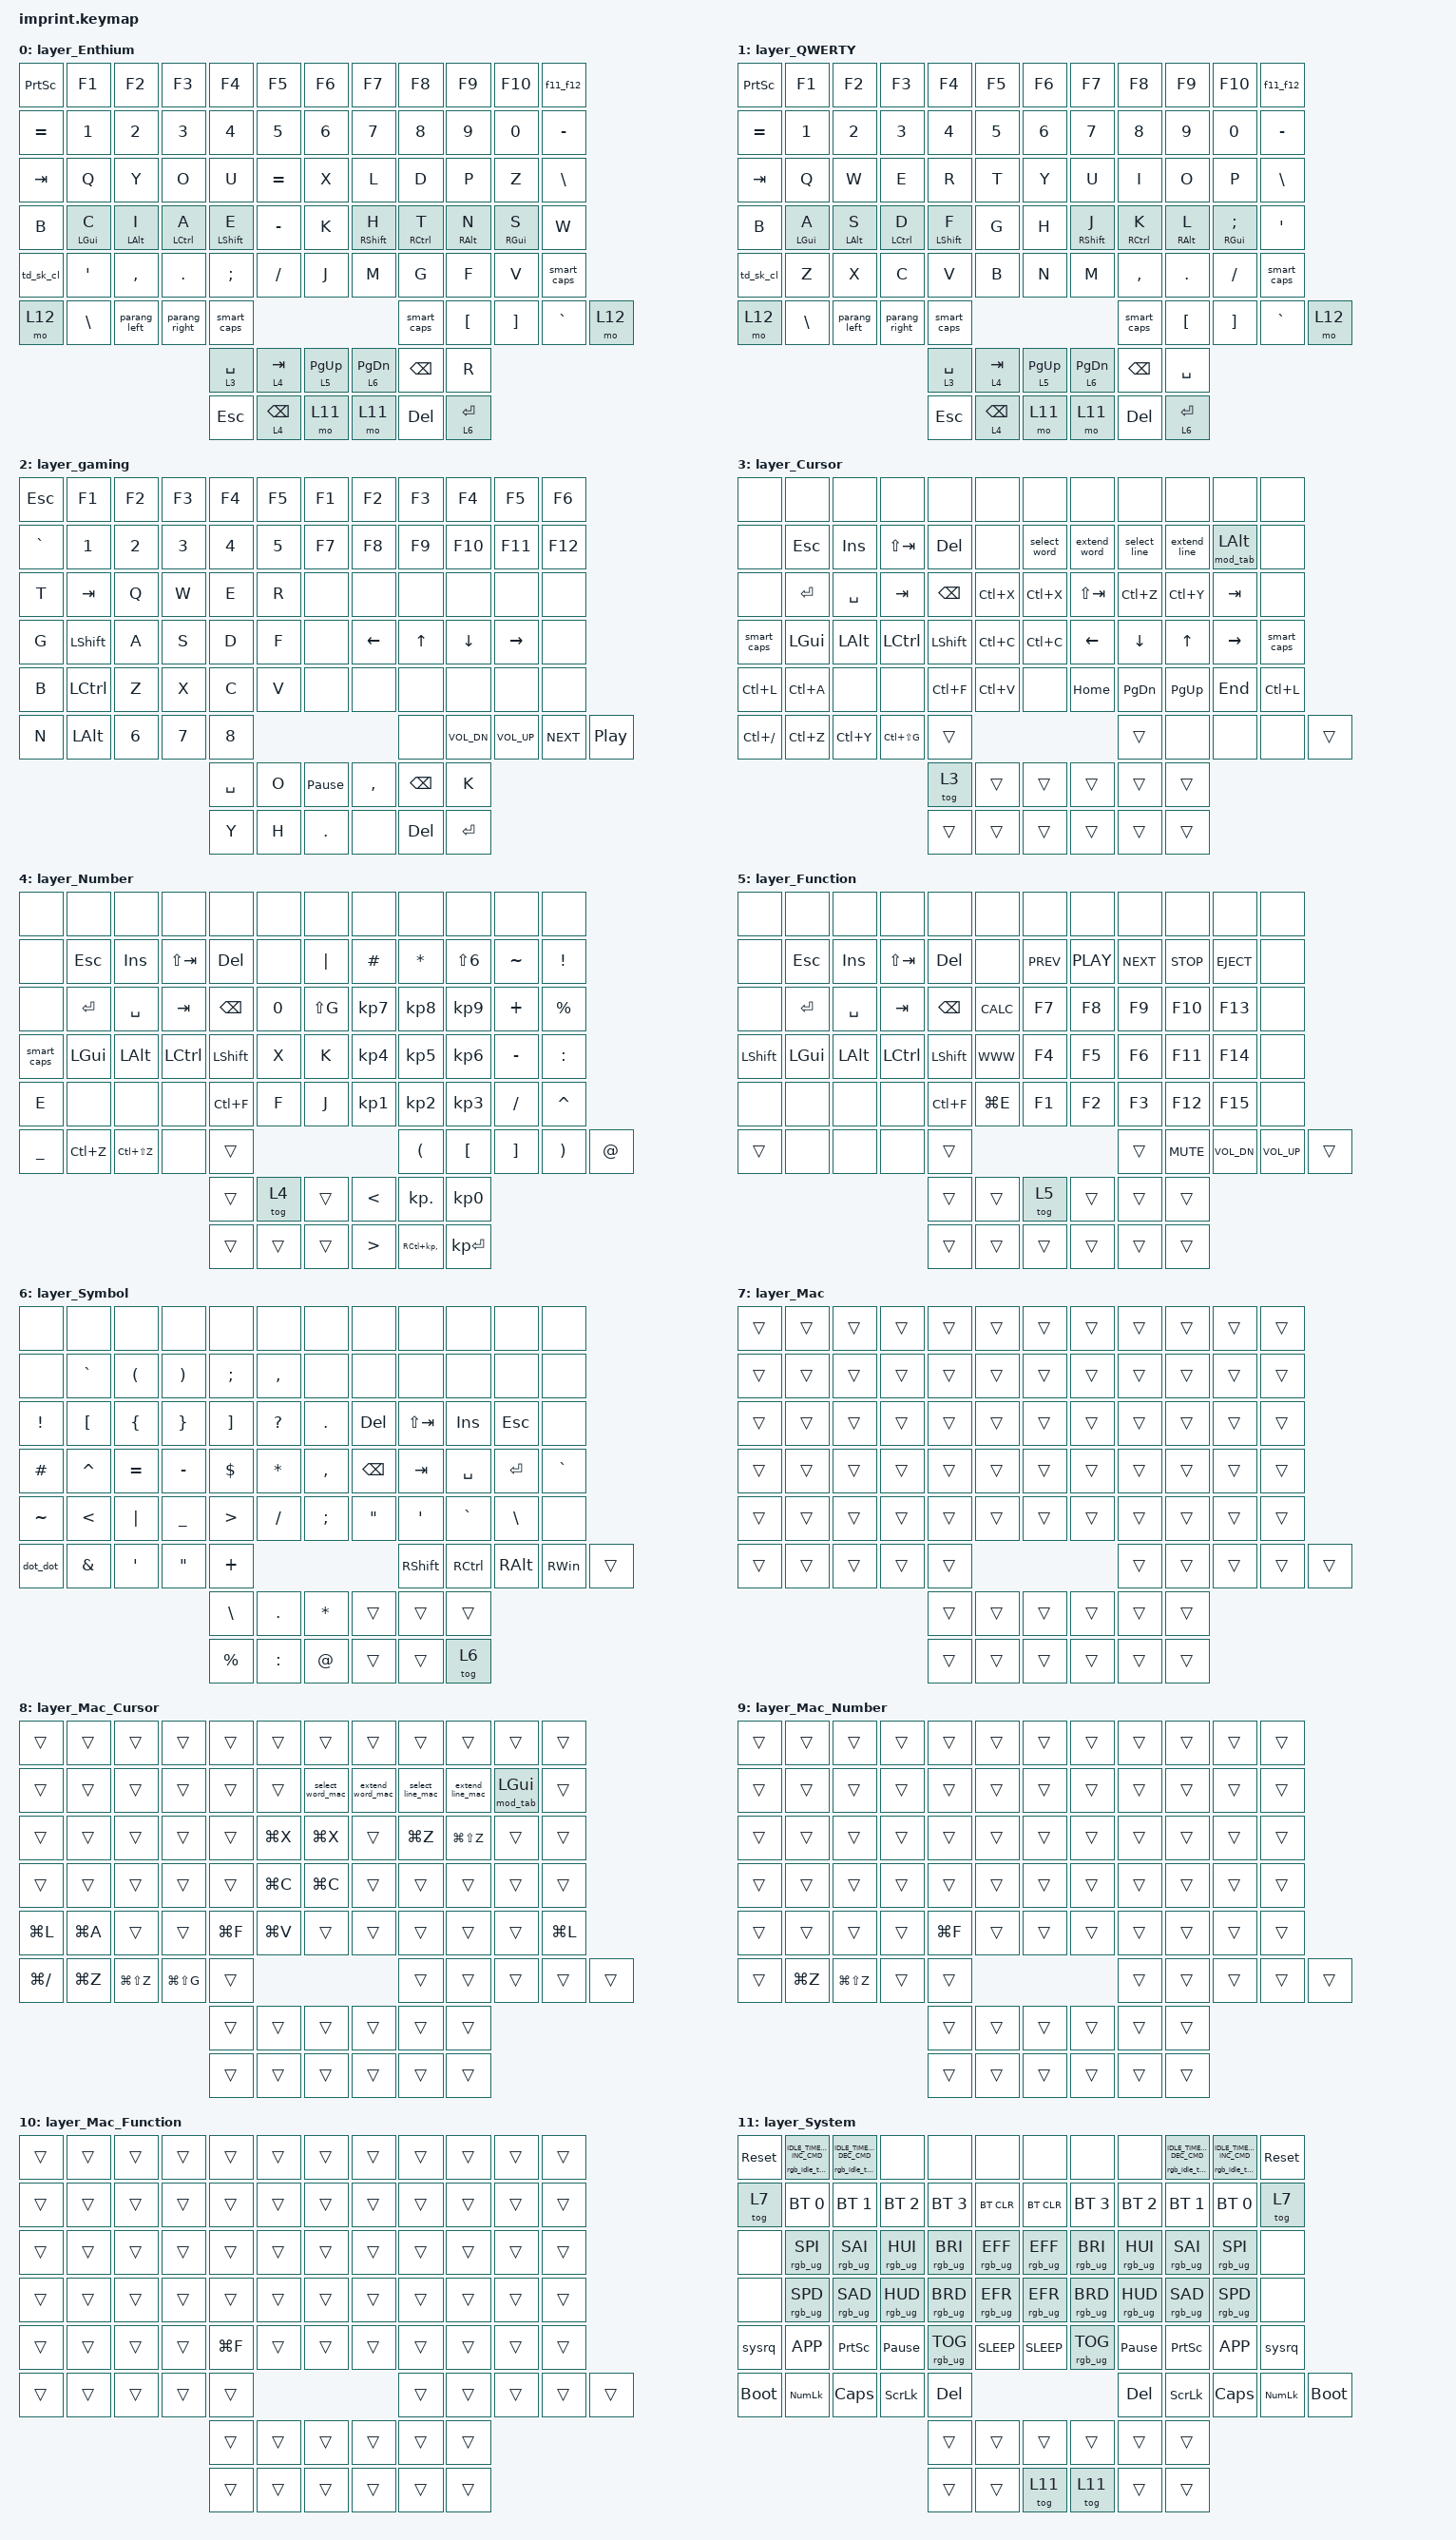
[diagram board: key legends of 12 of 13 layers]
#include <input/processors.dtsi>
#include <dt-bindings/zmk/input_transform.h>
#include <dt-bindings/zmk/hid_usage.h>
#include <behaviors.dtsi>
#include <behaviors/rgb_idle_timeout.dtsi>
#include <dt-bindings/zmk/bt.h>
#include <dt-bindings/zmk/keys.h>
#include <dt-bindings/zmk/rgb.h>
#include <dt-bindings/zmk/rgb_idle_timeout.h>

/ {
    // ========================================================================
    // ADVANCED BEHAVIORS (Adapted from Sunaku's "Glorious Engrammer")
    // ========================================================================

    behaviors {
        // 1. HOME ROW MODS (HRM) - BILATERAL COMBINATIONS
        // Sunaku's "Difficulty Level 2" translates to roughly 200ms tap terms 
        // with a 150ms streak decay. This ensures that at 90wpm, rolling keys 
        // won't accidentally trigger a Shift or Ctrl.

        hm_l: homerow_mods_left {
            compatible = "zmk,behavior-hold-tap";
            label = "HOMEROW_MODS_LEFT";
            #binding-cells = <2>;
            flavor = "balanced";
            tapping-term-ms = <200>;
            quick-tap-ms = <150>;
            require-prior-idle-ms = <50>;

            // NOTE: To make this strictly bilateral (only fires when you press
            // a key on the opposite hand), you must define your right hand key positions.
            // hold-trigger-key-positions = < 6 7 8 ... >;

            bindings = <&kp>, <&kp>;

            hold-trigger-key-positions = <70 76 77 71 78 72 73 74 75 79 80 81 6 7 8 9 10 11 18 19 20 21 22 23 30 31 32 33 34 35 42 43 44 45 46 47 54 55 56 57 58 59 65 66 67 68 69 75 37 38 39 40>;
        };

        hm_r: homerow_mods_right {
            compatible = "zmk,behavior-hold-tap";
            label = "HOMEROW_MODS_RIGHT";
            #binding-cells = <2>;
            flavor = "balanced";
            tapping-term-ms = <200>;
            quick-tap-ms = <150>;
            require-prior-idle-ms = <50>;

            // hold-trigger-key-positions = < 0 1 2 ... >; // Map to left hand keys

            bindings = <&kp>, <&kp>;

            hold-trigger-key-positions = <73 74 75 79 80 81 70 71 72 76 77 78 0 1 2 3 4 5 12 13 14 15 16 17 24 25 26 27 28 29 36 37 38 39 40 41 48 49 50 51 52 53 60 61 62 63 64 46 45 44 43>;
        };

        hm_l_sft: homerow_mods_left_shift {
            compatible = "zmk,behavior-hold-tap";
            label = "HOMEROW_MODS_LEFT_SHIFT";
            #binding-cells = <2>;
            flavor = "balanced";
            tapping-term-ms = <300>;
            quick-tap-ms = <150>;
            require-prior-idle-ms = <50>;
            hold-while-undecided;

            bindings = <&kp>, <&kp>;

            hold-trigger-key-positions = <70 76 77 71 78 72 73 74 75 79 80 81 6 7 8 9 10 11 18 19 20 21 22 23 30 31 32 33 34 35 42 43 44 45 46 47 54 55 56 57 58 59 65 66 67 68 69 75 37 38 39 40>;
        };

        hm_r_sft: homerow_mods_right_shift {
            compatible = "zmk,behavior-hold-tap";
            label = "HOMEROW_MODS_RIGHT_SHIFT";
            #binding-cells = <2>;
            flavor = "balanced";
            tapping-term-ms = <300>;
            quick-tap-ms = <150>;
            require-prior-idle-ms = <50>;
            hold-while-undecided;

            bindings = <&kp>, <&kp>;

            hold-trigger-key-positions = <73 74 75 79 80 81 70 71 72 76 77 78 0 1 2 3 4 5 12 13 14 15 16 17 24 25 26 27 28 29 36 37 38 39 40 41 48 49 50 51 52 53 60 61 62 63 64 46 45 44 43>;
        };

        // 2. THUMB LAYER ACCESS
        // Thumbs use a "balanced" flavor so that if you press a thumb and a key
        // almost simultaneously, it still registers as a layer shift.

        thumb: thumb_layer_access {
            compatible = "zmk,behavior-hold-tap";
            label = "THUMB_LAYER";
            #binding-cells = <2>;
            flavor = "balanced";
            tapping-term-ms = <200>;
            quick-tap-ms = <150>;
            bindings = <&mo>, <&kp>;
        };

        // 3. ONE-SHOT STICKY KEYS
        // For fast capitalization without holding shift. Tap once for next key, 
        // tap twice to lock.

        skq: sticky_key_quick_release {
            compatible = "zmk,behavior-sticky-key";
            label = "STICKY_KEY_QUICK";
            #binding-cells = <1>;
            bindings = <&kp>;
            release-after-ms = <500>;
            quick-release;
            ignore-modifiers;
        };

        // 4. SMART CAPS WORD
        // Automatically turns off caps when you hit space or a non-word character.

        smart_caps: caps_word {
            compatible = "zmk,behavior-caps-word";
            label = "SMART_CAPS";
            #binding-cells = <0>;
            continue-list = <UNDERSCORE MINUS BSPC DEL N1 N2 N3 N4 N5 N6 N7 N8 N9 N0>;
        };

        td_sk_cl: td_sticky_caps_tog {
            compatible = "zmk,behavior-tap-dance";
            label = "TD_SK_CL";
            #binding-cells = <0>;
            bindings = <&smart_caps>, <&kp CAPS>;

            tapping-term-ms = <170>;
        };

        f11_f12: f11_f12 {
            compatible = "zmk,behavior-tap-dance";
            label = "F11_F12";
            #binding-cells = <0>;
            bindings = <&kp F11>, <&kp F12>;
        };

        select_word: select_word {
            compatible = "zmk,behavior-mod-morph";
            #binding-cells = <0>;
            bindings = <&select_word_right>, <&select_word_left>;
            mods = <(MOD_LSFT|MOD_RSFT)>;
        };

        extend_word: extend_word {
            compatible = "zmk,behavior-mod-morph";
            #binding-cells = <0>;
            bindings = <&extend_word_right>, <&extend_word_left>;
            mods = <(MOD_LSFT|MOD_RSFT)>;
        };

        select_line: select_line {
            compatible = "zmk,behavior-mod-morph";
            #binding-cells = <0>;
            bindings = <&select_line_right>, <&select_line_left>;
            mods = <(MOD_LSFT|MOD_RSFT)>;
        };

        extend_line: extend_line {
            compatible = "zmk,behavior-mod-morph";
            #binding-cells = <0>;
            bindings = <&extend_line_right>, <&extend_line_left>;
            mods = <(MOD_LSFT|MOD_RSFT)>;
        };

        select_word_mac: select_word_mac {
            compatible = "zmk,behavior-mod-morph";
            #binding-cells = <0>;
            bindings = <&select_word_right_mac>, <&select_word_left_mac>;
            mods = <(MOD_LSFT|MOD_RSFT)>;
        };

        extend_word_mac: extend_word_mac {
            compatible = "zmk,behavior-mod-morph";
            #binding-cells = <0>;
            bindings = <&extend_word_right_mac>, <&extend_word_left_mac>;
            mods = <(MOD_LSFT|MOD_RSFT)>;
        };

        select_line_mac: select_line_mac {
            compatible = "zmk,behavior-mod-morph";
            #binding-cells = <0>;
            bindings = <&select_line_right_mac>, <&select_line_left_mac>;
            mods = <(MOD_LSFT|MOD_RSFT)>;
        };

        extend_line_mac: extend_line_mac {
            compatible = "zmk,behavior-mod-morph";
            #binding-cells = <0>;
            bindings = <&extend_line_right_mac>, <&extend_line_left_mac>;
            mods = <(MOD_LSFT|MOD_RSFT)>;
        };

        parang_left: parang_left {
            compatible = "zmk,behavior-mod-morph";
            #binding-cells = <0>;
            bindings = <&kp LPAR>, <&kp LESS_THAN>;
            mods = <(MOD_LSFT|MOD_RSFT)>;
        };

        parang_right: parang_right {
            compatible = "zmk,behavior-mod-morph";
            #binding-cells = <0>;
            bindings = <&kp RPAR>, <&kp GREATER_THAN>;
            mods = <(MOD_LSFT|MOD_RSFT)>;
        };
    };

    // ========================================================================
    // MACROS (Rolling bigrams and OS functions)
    // ========================================================================

    macros {
        dot_dot: dot_dot {
            compatible = "zmk,behavior-macro";
            label = "DOT_DOT";
            #binding-cells = <0>;
            wait-ms = <0>;
            tap-ms = <0>;
            bindings = <&kp DOT &kp DOT>;
        };

        // Windows/Linux Magic SysReq

        sysrq: linux_magic_sysrq {
            compatible = "zmk,behavior-macro";
            label = "SYSRQ";
            #binding-cells = <0>;
            wait-ms = <0>;
            tap-ms = <0>;
            bindings =
                <&macro_press>,
                <&kp LALT>,
                <&macro_tap>,
                <&kp PSCRN>,
                <&macro_release>,
                <&kp LALT>;
        };

        select_word_right: select_word_right {
            compatible = "zmk,behavior-macro";
            label = "SELECT_WORD_RIGHT";
            #binding-cells = <0>;
            wait-ms = <1>;
            tap-ms = <1>;
            bindings = <&kp LC(RIGHT) &kp LC(LEFT) &kp LC(LS(RIGHT))>;
        };

        select_word_left: select_word_left {
            compatible = "zmk,behavior-macro";
            label = "SELECT_WORD_LEFT";
            #binding-cells = <0>;
            wait-ms = <1>;
            tap-ms = <1>;
            bindings = <&kp LC(LEFT) &kp LC(RIGHT) &kp LC(LS(LEFT))>;
        };

        extend_word_right: extend_word_right {
            compatible = "zmk,behavior-macro";
            label = "EXTEND_WORD_RIGHT";
            #binding-cells = <0>;
            wait-ms = <1>;
            tap-ms = <1>;
            bindings = <&kp LC(LS(RIGHT))>;
        };

        extend_word_left: extend_word_left {
            compatible = "zmk,behavior-macro";
            label = "EXTEND_WORD_LEFT";
            #binding-cells = <0>;
            wait-ms = <1>;
            tap-ms = <1>;
            bindings = <&kp LC(LS(LEFT))>;
        };

        select_line_right: select_line_right {
            compatible = "zmk,behavior-macro";
            label = "SELECT_LINE_RIGHT";
            #binding-cells = <0>;
            wait-ms = <1>;
            tap-ms = <1>;
            bindings = <&kp HOME &kp LS(END)>;
        };

        select_line_left: select_line_left {
            compatible = "zmk,behavior-macro";
            label = "SELECT_LINE_LEFT";
            #binding-cells = <0>;
            wait-ms = <1>;
            tap-ms = <1>;
            bindings = <&kp END &kp LS(HOME)>;
        };

        extend_line_right: extend_line_right {
            compatible = "zmk,behavior-macro";
            label = "EXTEND_LINE_RIGHT";
            #binding-cells = <0>;
            wait-ms = <1>;
            tap-ms = <1>;
            bindings = <&kp LS(DOWN) &kp LS(END)>;
        };

        extend_line_left: extend_line_left {
            compatible = "zmk,behavior-macro";
            label = "EXTEND_LINE_LEFT";
            #binding-cells = <0>;
            wait-ms = <1>;
            tap-ms = <1>;
            bindings = <&kp LS(UP) &kp LS(HOME)>;
        };

        select_word_right_mac: select_word_right_mac {
            compatible = "zmk,behavior-macro";
            label = "SELECT_WORD_RIGHT_MAC";
            #binding-cells = <0>;
            wait-ms = <1>;
            tap-ms = <1>;
            bindings = <&kp LA(RIGHT) &kp LA(LEFT) &kp LA(LS(RIGHT))>;
        };

        select_word_left_mac: select_word_left_mac {
            compatible = "zmk,behavior-macro";
            label = "SELECT_WORD_LEFT_MAC";
            #binding-cells = <0>;
            wait-ms = <1>;
            tap-ms = <1>;
            bindings = <&kp LA(LEFT) &kp LA(RIGHT) &kp LA(LS(LEFT))>;
        };

        extend_word_right_mac: extend_word_right_mac {
            compatible = "zmk,behavior-macro";
            label = "EXTEND_WORD_RIGHT_MAC";
            #binding-cells = <0>;
            wait-ms = <1>;
            tap-ms = <1>;
            bindings = <&kp LA(LS(RIGHT))>;
        };

        extend_word_left_mac: extend_word_left_mac {
            compatible = "zmk,behavior-macro";
            label = "EXTEND_WORD_LEFT_MAC";
            #binding-cells = <0>;
            wait-ms = <1>;
            tap-ms = <1>;
            bindings = <&kp LA(LS(LEFT))>;
        };

        select_line_right_mac: select_line_right_mac {
            compatible = "zmk,behavior-macro";
            label = "SELECT_LINE_RIGHT_MAC";
            #binding-cells = <0>;
            wait-ms = <1>;
            tap-ms = <1>;
            bindings = <&kp LG(LEFT) &kp LG(LS(RIGHT))>;
        };

        select_line_left_mac: select_line_left_mac {
            compatible = "zmk,behavior-macro";
            label = "SELECT_LINE_LEFT_MAC";
            #binding-cells = <0>;
            wait-ms = <1>;
            tap-ms = <1>;
            bindings = <&kp LG(RIGHT) &kp LG(LS(LEFT))>;
        };

        extend_line_right_mac: extend_line_right_mac {
            compatible = "zmk,behavior-macro";
            label = "EXTEND_LINE_RIGHT_MAC";
            #binding-cells = <0>;
            wait-ms = <1>;
            tap-ms = <1>;
            bindings = <&kp LS(DOWN) &kp LG(LS(RIGHT))>;
        };

        extend_line_left_mac: extend_line_left_mac {
            compatible = "zmk,behavior-macro";
            label = "EXTEND_LINE_LEFT_MAC";
            #binding-cells = <0>;
            wait-ms = <1>;
            tap-ms = <1>;
            bindings = <&kp LS(UP) &kp LG(LS(LEFT))>;
        };

        mod_tab: mod_tab_switcher {
            compatible = "zmk,behavior-macro-one-param";
            label = "MOD_TAB";
            wait-ms = <0>;
            tap-ms = <0>;
            #binding-cells = <1>;
            bindings
                = <&macro_param_1to1>
                , <&macro_press &kp MACRO_PLACEHOLDER>
                , <&macro_tap &kp TAB>
                , <&macro_pause_for_release>
                , <&macro_param_1to1>
                , <&macro_release &kp MACRO_PLACEHOLDER>
                ;
        };
    };

    // ========================================================================
    // KEYMAP LAYERS
    // ========================================================================

    chosen { zmk,matrix-transform = &imprint_function_row_full_bottom_row; };

    combos {
        compatible = "zmk,combos";

        combo_gaming_toggle {
            timeout-ms = <50>;
            require-prior-idle-ms = <150>;
            key-positions = <48 61>;
            bindings = <&tog 2>;
            layers = <0 1 2 7>;
        };

        combo_mac_toggle {
            timeout-ms = <50>;
            require-prior-idle-ms = <150>;
            key-positions = <59 68>;
            bindings = <&tog 7>;
            layers = <0 1 7>;
        };

        combo_sticky_shift_left {
            timeout-ms = <50>;
            require-prior-idle-ms = <150>;
            key-positions = <70 77>;
            bindings = <&sk LSHFT>;
            layers = <0 1 7>;
        };

        combo_sticky_shift_right {
            timeout-ms = <50>;
            require-prior-idle-ms = <150>;
            key-positions = <75 80>;
            bindings = <&sk RSHFT>;
            layers = <0 1 7>;
        };

        combo_caps_word_left {
            timeout-ms = <50>;
            require-prior-idle-ms = <150>;
            key-positions = <76 77>;
            bindings = <&smart_caps>;
            layers = <0 1 7>;
        };

        combo_caps_word_right {
            timeout-ms = <50>;
            require-prior-idle-ms = <150>;
            key-positions = <81 80>;
            bindings = <&smart_caps>;
            layers = <0 1 7>;
        };

        combo_caps_lock_left {
            timeout-ms = <50>;
            require-prior-idle-ms = <150>;
            key-positions = <71 78>;
            bindings = <&kp CAPS>;
            layers = <0 1 7>;
        };

        combo_caps_lock_right {
            timeout-ms = <50>;
            require-prior-idle-ms = <150>;
            key-positions = <74 79>;
            bindings = <&kp CAPS>;
            layers = <0 1 7>;
        };

        combo_alt_tab {
            timeout-ms = <50>;
            require-prior-idle-ms = <150>;
            key-positions = <70 76>;
            bindings = <&mod_tab LALT>;
            layers = <0 1 7>;
        };

        combo_ctrl_tab {
            timeout-ms = <50>;
            require-prior-idle-ms = <150>;
            key-positions = <71 77>;
            bindings = <&mod_tab LCTRL>;
            layers = <0 1 7>;
        };

        combo_win_tab {
            timeout-ms = <50>;
            require-prior-idle-ms = <150>;
            key-positions = <72 78>;
            bindings = <&mod_tab LGUI>;
            layers = <0 1 7>;
        };

        combo_sticky_altgr_left {
            timeout-ms = <50>;
            require-prior-idle-ms = <150>;
            key-positions = <70 71>;
            bindings = <&sk RALT>;
            layers = <0 1 7>;
        };

        combo_sticky_altgr_right {
            timeout-ms = <50>;
            require-prior-idle-ms = <150>;
            key-positions = <75 74>;
            bindings = <&sk RALT>;
            layers = <0 1 7>;
        };

        combo_sticky_win_left {
            timeout-ms = <50>;
            require-prior-idle-ms = <150>;
            key-positions = <71 72>;
            bindings = <&sk LGUI>;
            layers = <0 1 7>;
        };

        combo_sticky_win_right {
            timeout-ms = <50>;
            require-prior-idle-ms = <150>;
            key-positions = <74 73>;
            bindings = <&sk RGUI>;
            layers = <0 1 7>;
        };

        combo_hyper {
            timeout-ms = <50>;
            require-prior-idle-ms = <150>;
            key-positions = <75 81>;
            bindings = <&kp LG(LA(LC(LSHFT)))>;
            layers = <0 1 7>;
        };

        combo_meh {
            timeout-ms = <50>;
            require-prior-idle-ms = <150>;
            key-positions = <74 80>;
            bindings = <&kp LA(LC(LSHFT))>;
            layers = <0 1 7>;
        };

        combo_turbo {
            timeout-ms = <50>;
            require-prior-idle-ms = <150>;
            key-positions = <73 79>;
            bindings = <&kp LC(LSHFT)>;
            layers = <0 1 7>;
        };

        combo_base_reset_left {
            timeout-ms = <50>;
            require-prior-idle-ms = <150>;
            key-positions = <70 71 72>;
            bindings = <&to 0>;
            layers = <1 3 4 5 6 7 8 9 10 11>;
        };

        combo_base_reset_right {
            timeout-ms = <50>;
            require-prior-idle-ms = <150>;
            key-positions = <75 74 73>;
            bindings = <&to 0>;
            layers = <1 3 4 5 6 7 8 9 10 11>;
        };
    };

    keymap {
        compatible = "zmk,keymap";

        layer_Enthium {
            bindings = <
&kp PSCRN  &kp F1        &kp F2        &kp F3         &kp F4          &kp F5                 &kp F6  &kp F7         &kp F8         &kp F9        &kp F10       &f11_f12
&kp EQUAL  &kp N1        &kp N2        &kp N3         &kp N4          &kp N5                 &kp N6  &kp N7         &kp N8         &kp N9        &kp N0        &kp MINUS
&kp TAB    &kp Q         &kp Y         &kp O          &kp U           &kp EQUAL              &kp X   &kp L          &kp D          &kp P         &kp Z         &kp BSLH
&kp B      &hm_l LGUI C  &hm_l LALT I  &hm_l LCTRL A  &hm_l_sft LSHFT E   &kp MINUS              &kp K   &hm_r_sft RSHFT H  &hm_r RCTRL T  &hm_r RALT N  &hm_r RGUI S  &kp W
&td_sk_cl  &kp SQT       &kp COMMA     &kp DOT        &kp SEMI        &kp FSLH               &kp J   &kp M          &kp G          &kp F         &kp V         &smart_caps
&mo 12     &kp BSLH      &parang_left      &parang_right       &smart_caps                                    &smart_caps    &kp LBKT       &kp RBKT      &kp GRAVE     &mo 12
                                                      &thumb 3 SPACE  &thumb 4 TAB  &thumb 5 PG_UP  &thumb 6 PG_DN  &kp BSPC  &kp R
                                                      &kp ESC        &thumb 4 BSPC &mo 11   &mo 11  &kp DEL        &thumb 6 RET
            >;
        };

        layer_QWERTY {
            bindings = <
&kp PSCRN  &kp F1        &kp F2        &kp F3         &kp F4          &kp F5                 &kp F6    &kp F7         &kp F8          &kp F9        &kp F10          &f11_f12
&kp EQUAL  &kp N1        &kp N2        &kp N3         &kp N4          &kp N5                 &kp N6    &kp N7         &kp N8          &kp N9        &kp N0           &kp MINUS
&kp TAB    &kp Q         &kp W         &kp E          &kp R           &kp T                  &kp Y     &kp U          &kp I           &kp O         &kp P            &kp BSLH
&kp B      &hm_l LGUI A  &hm_l LALT S  &hm_l LCTRL D  &hm_l_sft LSHFT F   &kp G                  &kp H     &hm_r_sft RSHFT J  &hm_r RCTRL K   &hm_r RALT L  &hm_r RGUI SEMI  &kp SQT
&td_sk_cl  &kp Z         &kp X         &kp C          &kp V           &kp B                  &kp N     &kp M          &kp COMMA       &kp DOT       &kp FSLH         &smart_caps
&mo 12     &kp BSLH      &parang_left      &parang_right       &smart_caps                                      &smart_caps    &kp LBKT        &kp RBKT      &kp GRAVE        &mo 12
                                                      &thumb 3 SPACE  &thumb 4 TAB  &thumb 5 PG_UP  &thumb 6 PG_DN  &kp BSPC  &kp SPACE
                                                      &kp ESC        &thumb 4 BSPC &mo 11   &mo 11    &kp DEL        &thumb 6 RET
            >;
        };

        layer_gaming {
            bindings = <
&kp ESCAPE  &kp F1            &kp F2        &kp F3  &kp F4        &kp F5                     &kp F1     &kp F2         &kp F3        &kp F4        &kp F5      &kp F6
&kp GRAVE   &kp N1            &kp N2        &kp N3  &kp N4        &kp N5                     &kp F7     &kp F8         &kp F9        &kp F10       &kp F11     &kp F12
&kp T       &kp TAB           &kp Q         &kp W   &kp E         &kp R                      &none      &none          &none         &none         &none       &none
&kp G       &kp LEFT_SHIFT    &kp A         &kp S   &kp D         &kp F                      &none      &kp LEFT       &kp UP        &kp DOWN      &kp RIGHT   &none
&kp B       &kp LEFT_CONTROL  &kp Z         &kp X   &kp C         &kp V                      &none      &none          &none         &none         &none       &none
&kp N       &kp LEFT_ALT      &kp NUMBER_6  &kp N7  &kp NUMBER_8                                        &none          &kp C_VOL_DN  &kp C_VOL_UP  &kp C_NEXT  &kp C_PLAY_PAUSE
                                                    &kp SPACE     &kp O   &kp PAUSE_BREAK    &kp COMMA  &kp BACKSPACE  &kp K
                                                    &kp Y         &kp H   &kp PERIOD         &none      &kp DEL        &kp ENTER
            >;
        };

        layer_Cursor {
            bindings = <
&none          &none      &none      &none          &none      &none                &none      &none        &none      &none      &none      &none
&none          &kp ESC    &kp INS    &kp LS(TAB)    &kp DEL    &none                &select_word  &extend_word  &select_line  &extend_line  &mod_tab LALT  &none
&none          &kp RET    &kp SPACE  &kp TAB        &kp BSPC   &kp LC(X)            &kp LC(X)  &kp LS(TAB)  &kp LC(Z)  &kp LC(Y)  &kp TAB    &none
&smart_caps    &kp LGUI   &kp LALT   &kp LCTRL      &kp LSHFT  &kp LC(C)            &kp LC(C)  &kp LEFT     &kp DOWN   &kp UP     &kp RIGHT  &smart_caps
&kp LC(L)      &kp LC(A)  &none      &none          &kp LC(F)  &kp LC(V)            &none      &kp HOME     &kp PG_DN  &kp PG_UP  &kp END    &kp LC(L)
&kp LC(SLASH)  &kp LC(Z)  &kp LC(Y)  &kp LC(LS(G))  &trans                                     &trans       &none      &none      &none      &trans
                                                    &tog 3     &trans     &trans    &trans     &trans       &trans
                                                    &trans     &trans     &trans    &trans     &trans       &trans
            >;
        };

        layer_Number {
            bindings = <
&none           &none      &none          &none        &none      &none             &none             &none                 &none         &none       &none                  &none
&none           &kp ESC    &kp INS        &kp LS(TAB)  &kp DEL    &none             &kp PIPE          &kp HASH              &kp STAR      &kp LS(N6)  &kp TILDE              &kp EXCLAMATION
&none           &kp RET    &kp SPACE      &kp TAB      &kp BSPC   &kp N0            &kp LS(G)         &kp KP_N7             &kp KP_N8     &kp KP_N9   &kp PLUS               &kp PERCENT
&smart_caps     &kp LGUI   &kp LALT       &kp LCTRL    &kp LSHFT  &kp X             &kp K             &kp KP_N4             &kp KP_N5     &kp KP_N6   &kp MINUS              &kp COLON
&kp E           &none      &none          &none        &kp LC(F)  &kp F             &kp J             &kp KP_N1             &kp KP_N2     &kp KP_N3   &kp FSLH               &kp CARET
&kp UNDERSCORE  &kp LC(Z)  &kp LC(LS(Z))  &none        &trans                                         &kp LEFT_PARENTHESIS  &kp LBKT      &kp RBKT    &kp RIGHT_PARENTHESIS  &kp AT_SIGN
                                                       &trans     &tog 4  &trans    &kp LESS_THAN     &kp KP_DOT            &kp KP_N0
                                                       &trans     &trans  &trans    &kp GREATER_THAN  &kp RC(KP_COMMA)      &kp KP_ENTER
            >;
        };

        layer_Function {
            bindings = <
&none      &none     &none      &none        &none      &none                 &none       &none       &none       &none         &none         &none
&none      &kp ESC   &kp INS    &kp LS(TAB)  &kp DEL    &none                 &kp C_PREV  &kp C_PLAY  &kp C_NEXT  &kp C_STOP    &kp C_EJECT   &none
&none      &kp RET   &kp SPACE  &kp TAB      &kp BSPC   &kp K_CALC            &kp F7      &kp F8      &kp F9      &kp F10       &kp F13       &none
&kp LSHFT  &kp LGUI  &kp LALT   &kp LCTRL    &kp LSHFT  &kp K_WWW             &kp F4      &kp F5      &kp F6      &kp F11       &kp F14       &none
&none      &none     &none      &none        &kp LC(F)  &kp LG(E)             &kp F1      &kp F2      &kp F3      &kp F12       &kp F15       &none
&trans     &none     &none      &none        &trans                                       &trans      &kp C_MUTE  &kp C_VOL_DN  &kp C_VOL_UP  &trans
                                             &trans     &trans      &tog 5    &trans      &trans      &trans
                                             &trans     &trans      &trans    &trans      &trans      &trans
            >;
        };

        layer_Symbol {
            bindings = <
&none            &none          &none                 &none                  &none             &none                        &none          &none              &none             &none      &none          &none
&none            &kp GRAVE      &kp LEFT_PARENTHESIS  &kp RIGHT_PARENTHESIS  &kp SEMI          &kp COMMA                    &none          &none              &none             &none      &none          &none
&kp EXCLAMATION  &kp LBKT       &kp LEFT_BRACE        &kp RIGHT_BRACE        &kp RBKT          &kp QUESTION                 &kp DOT        &kp DEL            &kp LS(TAB)       &kp INS    &kp ESC        &none
&kp POUND        &kp CARET      &kp EQUAL             &kp MINUS              &kp DOLLAR        &kp STAR                     &kp COMMA      &kp BSPC           &kp TAB           &kp SPACE  &kp RET        &kp GRAVE
&kp TILDE        &kp LESS_THAN  &kp PIPE              &kp UNDERSCORE         &kp GREATER_THAN  &kp FSLH                     &kp SEMICOLON  &kp DOUBLE_QUOTES  &kp SINGLE_QUOTE  &kp GRAVE  &kp BACKSLASH  &none
&dot_dot         &kp AMPERSAND  &kp SINGLE_QUOTE      &kp DOUBLE_QUOTES      &kp PLUS                                                      &kp RIGHT_SHIFT    &kp RCTRL         &kp RALT   &kp RIGHT_WIN  &trans
                                                                             &kp BACKSLASH     &kp PERIOD    &kp STAR       &trans         &trans             &trans
                                                                             &kp PERCENT       &kp COLON     &kp AT_SIGN    &trans         &trans             &tog 6
            >;
        };

        layer_Mac {
            bindings = <
&trans  &trans  &trans  &trans  &trans  &trans      &trans  &trans  &trans  &trans  &trans  &trans
&trans  &trans  &trans  &trans  &trans  &trans      &trans  &trans  &trans  &trans  &trans  &trans
&trans  &trans  &trans  &trans  &trans  &trans      &trans  &trans  &trans  &trans  &trans  &trans
&trans  &trans  &trans  &trans  &trans  &trans      &trans  &trans  &trans  &trans  &trans  &trans
&trans  &trans  &trans  &trans  &trans  &trans      &trans  &trans  &trans  &trans  &trans  &trans
&trans  &trans  &trans  &trans  &trans              &trans  &trans  &trans  &trans  &trans
                                &trans  &trans  &trans    &trans  &trans  &trans
                                &trans  &trans  &trans    &trans  &trans  &trans
            >;
        };

        layer_Mac_Cursor {
            bindings = <
&trans  &trans  &trans  &trans  &trans  &trans      &trans  &trans  &trans  &trans  &trans  &trans
&trans  &trans  &trans  &trans  &trans  &trans      &select_word_mac  &extend_word_mac  &select_line_mac  &extend_line_mac  &mod_tab LGUI  &trans
&trans  &trans  &trans  &trans  &trans  &kp LG(X)   &kp LG(X)  &trans  &kp LG(Z)  &kp LG(LS(Z))  &trans  &trans
&trans  &trans  &trans  &trans  &trans  &kp LG(C)   &kp LG(C)  &trans  &trans  &trans  &trans  &trans
&kp LG(L)  &kp LG(A)  &trans  &trans  &kp LG(F)  &kp LG(V)      &trans  &trans  &trans  &trans  &trans  &kp LG(L)
&kp LG(SLASH)  &kp LG(Z)  &kp LG(LS(Z))  &kp LG(LS(G))  &trans              &trans  &trans  &trans  &trans  &trans
                                &trans  &trans  &trans    &trans  &trans  &trans
                                &trans  &trans  &trans    &trans  &trans  &trans
            >;
        };

        layer_Mac_Number {
            bindings = <
&trans  &trans  &trans  &trans  &trans  &trans      &trans  &trans  &trans  &trans  &trans  &trans
&trans  &trans  &trans  &trans  &trans  &trans      &trans  &trans  &trans  &trans  &trans  &trans
&trans  &trans  &trans  &trans  &trans  &trans      &trans  &trans  &trans  &trans  &trans  &trans
&trans  &trans  &trans  &trans  &trans  &trans      &trans  &trans  &trans  &trans  &trans  &trans
&trans  &trans  &trans  &trans  &kp LG(F)  &trans   &trans  &trans  &trans  &trans  &trans  &trans
&trans  &kp LG(Z)  &kp LG(LS(Z))  &trans  &trans              &trans  &trans  &trans  &trans  &trans
                                &trans  &trans  &trans    &trans  &trans  &trans
                                &trans  &trans  &trans    &trans  &trans  &trans
            >;
        };

        layer_Mac_Function {
            bindings = <
&trans  &trans  &trans  &trans  &trans  &trans      &trans  &trans  &trans  &trans  &trans  &trans
&trans  &trans  &trans  &trans  &trans  &trans      &trans  &trans  &trans  &trans  &trans  &trans
&trans  &trans  &trans  &trans  &trans  &trans      &trans  &trans  &trans  &trans  &trans  &trans
&trans  &trans  &trans  &trans  &trans  &trans      &trans  &trans  &trans  &trans  &trans  &trans
&trans  &trans  &trans  &trans  &kp LG(F)  &trans   &trans  &trans  &trans  &trans  &trans  &trans
&trans  &trans  &trans  &trans  &trans              &trans  &trans  &trans  &trans  &trans
                                &trans  &trans  &trans    &trans  &trans  &trans
                                &trans  &trans  &trans    &trans  &trans  &trans
            >;
        };

        layer_System {
            bindings = <
&sys_reset   &rgb_idle_timeout RGB_IDLE_TIMEOUT_INC_CMD  &rgb_idle_timeout RGB_IDLE_TIMEOUT_DEC_CMD  &none  &none  &none    &none  &none  &none  &rgb_idle_timeout RGB_IDLE_TIMEOUT_DEC_CMD  &rgb_idle_timeout RGB_IDLE_TIMEOUT_INC_CMD  &sys_reset
&tog 7       &bt BT_SEL 0     &bt BT_SEL 1     &bt BT_SEL 2     &bt BT_SEL 3     &bt BT_CLR                 &bt BT_CLR       &bt BT_SEL 3     &bt BT_SEL 2     &bt BT_SEL 1     &bt BT_SEL 0     &tog 7
&none        &rgb_ug RGB_SPI  &rgb_ug RGB_SAI  &rgb_ug RGB_HUI  &rgb_ug RGB_BRI  &rgb_ug RGB_EFF            &rgb_ug RGB_EFF  &rgb_ug RGB_BRI  &rgb_ug RGB_HUI  &rgb_ug RGB_SAI  &rgb_ug RGB_SPI  &none
&none        &rgb_ug RGB_SPD  &rgb_ug RGB_SAD  &rgb_ug RGB_HUD  &rgb_ug RGB_BRD  &rgb_ug RGB_EFR            &rgb_ug RGB_EFR  &rgb_ug RGB_BRD  &rgb_ug RGB_HUD  &rgb_ug RGB_SAD  &rgb_ug RGB_SPD  &none
&sysrq       &kp K_APP        &kp PSCRN        &kp PAUSE_BREAK  &rgb_ug RGB_TOG  &kp C_SLEEP                &kp C_SLEEP      &rgb_ug RGB_TOG  &kp PAUSE_BREAK  &kp PSCRN        &kp K_APP        &sysrq
&bootloader  &kp KP_NUMLOCK   &kp CAPS         &kp SLCK         &kp DELETE                                                   &kp DELETE       &kp SLCK         &kp CAPS         &kp KP_NUMLOCK   &bootloader
                                                                &trans           &trans           &trans    &trans           &trans           &trans
                                                                &trans           &trans           &tog 11    &tog 11           &trans           &trans
            >;
        };

        layer_Lower {
            bindings = <
&none  &none  &none  &none  &none  &none      &none  &none  &none  &none  &none  &none
&to 0  &to 1  &none  &none  &none  &none      &none  &none  &none  &none  &none  &none
&none  &none  &none  &none  &none  &none      &none  &none  &none  &none  &none  &none
&none  &none  &none  &none  &none  &none      &none  &none  &none  &none  &none  &none
&none  &none  &none  &none  &none  &none      &none  &none  &none  &none  &none  &none
&none  &none  &none  &none  &none              &none  &none  &none  &none  &none
                                &tog 3  &tog 4  &tog 5     &tog 6  &none  &none
                                &none   &tog 4  &tog 11    &tog 11  &none  &tog 6
            >;
        };
    };

    conditional_layers {
        compatible = "zmk,conditional-layers";

        if_Cursor_then_Mac_Cursor {
            if-layers = <7 3>;
            then-layer = <8>;
        };

        if_Number_then_Mac_Number {
            if-layers = <7 4>;
            then-layer = <9>;
        };

        if_Function_then_Mac_Function {
            if-layers = <7 5>;
            then-layer = <10>;
        };
    };
};
